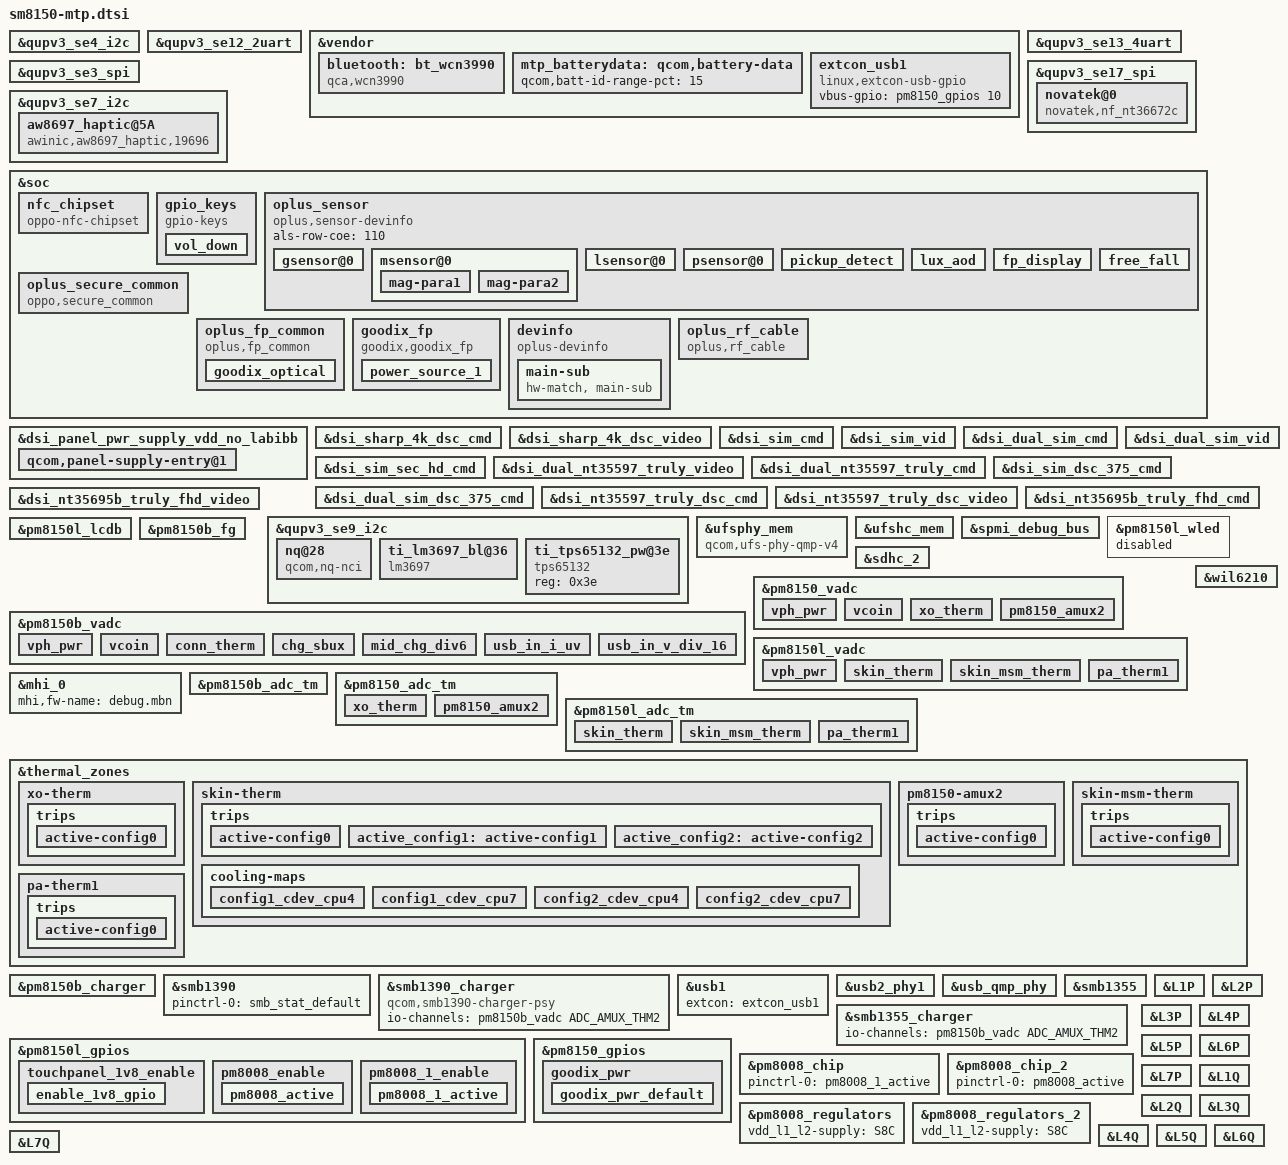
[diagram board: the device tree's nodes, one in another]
/* Copyright (c) 2017-2020, The Linux Foundation. All rights reserved.
 *
 * This program is free software; you can redistribute it and/or modify
 * it under the terms of the GNU General Public License version 2 and
 * only version 2 as published by the Free Software Foundation.
 *
 * This program is distributed in the hope that it will be useful,
 * but WITHOUT ANY WARRANTY; without even the implied warranty of
 * MERCHANTABILITY or FITNESS FOR A PARTICULAR PURPOSE.  See the
 * GNU General Public License for more details.
 */

#include <dt-bindings/gpio/gpio.h>
#include <dt-bindings/input/input.h>

#include "sm8150-pmic-overlay.dtsi"
#include "sm8150-sde-display.dtsi"
#include "sm8150-camera-sensor-mtp.dtsi"
#include "sm8150-thermal-overlay.dtsi"

&qupv3_se4_i2c {
#address-cells = <1>;
#size-cells = <0>;

#include "smb1390.dtsi"
#include "smb1355.dtsi"
/*#ifdef VENDOR_EDIT*/
/*zhixian.Mai@camera, 2019/06/21, Add for pm8008 driver*/
#include "pm8008.dtsi"
/*#endif*/
};

&qupv3_se12_2uart {
	status = "ok";
};

&vendor {
	bluetooth: bt_wcn3990 {
		compatible = "qca,wcn3990";
		qca,bt-vdd-core-supply = <&pm8150_l7>;
		qca,bt-vdd-pa-supply = <&pm8150l_l2>;
		qca,bt-vdd-ldo-supply = <&pm8150l_l11>;

		qca,bt-vdd-core-voltage-level = <1800000 1800000>;
		qca,bt-vdd-pa-voltage-level = <1304000 1304000>;
		qca,bt-vdd-ldo-voltage-level = <3312000 3312000>;

		qca,bt-vdd-core-current-level = <0>; /* LPM/PFM */
		qca,bt-vdd-pa-current-level = <0>; /* LPM/PFM */
		qca,bt-vdd-ldo-current-level = <0>; /* LPM/PFM */
	};

	mtp_batterydata: qcom,battery-data {
		qcom,batt-id-range-pct = <15>;
		#include "fg-gen4-batterydata-alium-3600mah.dtsi"
	};

	extcon_usb1: extcon_usb1 {
		compatible = "linux,extcon-usb-gpio";
		vbus-gpio = <&pm8150_gpios 10 GPIO_ACTIVE_HIGH>;
		//id-gpio = <&tlmm 101 GPIO_ACTIVE_HIGH>;
		//#ifdef VENDOR_EDIT /* tongfeng.Huang@BSP.CHG.Basic, 2018/01/08,  Add for charging chgID */
		//vbus-out-gpio = <&pm8150_gpios 9 GPIO_ACTIVE_HIGH>;
		//#endif

		pinctrl-names = "default";
		/*#ifdef VENDOR_EDIT*/
		//modify by Long.Liu 20190101, for fingerprint power gpio
		//pinctrl-0 = <&usb2_vbus_det_default
		//	     &usb2_id_det_default
		//	     &usb2_vbus_boost_default>;
		/*#endif*/
	};
};

&qupv3_se13_4uart {
	status = "ok";
};

&qupv3_se3_spi {
	status = "ok";
};

&qupv3_se4_i2c {
	status = "ok";
};
/*liuchao@BSP.TP.Function, 2019/11/27, add for novatek noflash TP*/
&qupv3_se17_spi {
	/* Himax device tree node */
	status = "ok";
	#address-cells = <1>;
	#size-cells = <0>;
	
	novatek@0 {
		compatible = "novatek,nf_nt36672c";
		reg = <0>;
		chip-name = "NT36672C_NF";
		status = "ok";

		spi-max-frequency = <15000000>; //4800000,9600000,15000000,19200000
		reset-gpio = <&tlmm 54 0x00>;
		interrupt-parent = <&tlmm>;
		interrupts = <122 0x0>;
		irq-gpio = <&tlmm 122 0x2002>;
		/*lcd-reset-gpio = <&tlmm 56 0x00>;*/
		cs-gpio = <&tlmm 58 0x01>;
		touchpanel,tx-rx-num = <18 36>;
		touchpanel,max-num-support = <10>;
		touchpanel,panel-coords = <1080 2400>;
		touchpanel,display-coords = <1080 2400>;
		touchpanel,touchmajor-limit = <0 54>;

		pinctrl-names = "default", "suspend";
		pinctrl-0 = <&ts_int_active &ts_reset_active>;
		pinctrl-1 = <&ts_int_suspend &ts_reset_suspend>;
                vid_len = <7>;
                tp_type = <6>;// type of tp_dev ,TP_JDI = 6;
                platform_support_project = <19696 19751 19752 19753 19700>;
                platform_support_project_dir = <19696 20682 20682 20682 20682>;
                platform_support_project_commandline = "nt36672c", "nt36672c", "nt36672c", "nt36672c", "nt36672c";

		incell_screen;
		fw_edge_limit_support;
		black_gesture_support;
		charger_pump_support;
		headset_pump_support;
		esd_handle_support;
		//spurious_fingerprint_support;
		//lcd_trigger_fp_check;
		black_gesture_test_support;
		noflash_support;
		smart_gesture_support;
		new_set_irq_wake_support;
		pressure_report_support;
		fw_update_app_support;
		game_switch_support;
		drlimit_remove_support;
		lcd_trigger_load_tp_fw_support;
		fw_update_in_probe_with_headfile;
		touchpanel,button-type = <4>;
		cs_gpio_need_pull;
	};
};
//#ifdef OPLUS_FEATURE_TP_BASIC
//#Chen.Pan@BSP.CHG.Misc, 2020/09/29, modify for aw8697
&qupv3_se7_i2c  {
    status = "okay";
	/* AWINIC AW8697 Haptic */
	aw8697_haptic@5A {
		compatible = "awinic,aw8697_haptic,19696";
		reg = <0x5A>;
		reset-gpio = <&tlmm 116 0>;
		irq-gpio = <&tlmm 24 0>;
		status = "okay";
        qcom,device_id = <832>;//19065

		pinctrl-names = "default";
		pinctrl-0 = <&aw_irq_gpio_default>;
	};
	/* AWINIC AW8697 Haptic End */
};
//#endif
&soc {
	//#ifdef OPLUS_FEATURE_CONNFCSOFT
	//#Zhangnan@Connectivity.NFC.BASIC.8126, 2019/09/09, Modify for : RTCID:2896930 CON_NFC_SOFT
	nfc_chipset {
		compatible = "oppo-nfc-chipset";
		chipset-19696-32 = "SN100T";
		chipset-19696-33 = "SN100T";
		chipset-19696-34 = "SN100T";
	};
	//#endif /* OPLUS_FEATURE_CONNFCSOFT */
	gpio_keys {
		compatible = "gpio-keys";
		label = "gpio-keys";

		pinctrl-names = "default";
		pinctrl-0 = <&key_vol_down_default>;

		vol_down {
			label = "volume_down";
			gpios = <&pm8150_gpios 7 GPIO_ACTIVE_LOW>;
			linux,input-type = <1>;
			linux,code = <KEY_VOLUMEDOWN>;
			gpio-key,wakeup;
			debounce-interval = <15>;
			linux,can-disable;
		};
	};

	//#ifdef OPLUS_FEATURE_SENSOR_SMEM
	/*yajie.chen @BSP.sensor, 2020/04/03, Add for sensor dts*/
	/*enum sensor_id { OPPO_ACCEL,OPPO_GYRO,OPPO_MAG,OPPO_LIGHT,OPPO_PROXIMITY,OPPO_SAR,OPPO_CT,OPPO_BAROMETER,SENSORS_NUM};*/
	oplus_sensor {
		compatible = "oplus,sensor-devinfo";
		als-row-coe = <110>;
		/*enum {LSM6DSM = 0x01, BMI160 = 0x02, LSM6DS3 = 0x04};*/
		gsensor@0 {
			sensor-name = <0x01>;//LSM6DSM
			sensor-direction = <6>;
			sensor-index = <0>;//source num
			sensor-type = <0>;//OPPO_ACCEL
		};
		/* enum {AKM0991X = 0x01, MMC5603 = 0x02};*/
		msensor@0 {
			sensor-name = <0x2>;//MMC5603
			sensor-direction = <0>;
			sensor-index = <1>;
			sensor-type = <2>;//OPPO_MAG
			mag-para1 {
				parameter-number= <18>;
				modem-type-num = <2>;
				match-modem-type = <10 11>; //modem-type  19711=10, 19698=11 those modemType use NFC
				soft-mag-parameter = <9614 0 2741 0 201 1 1436 0 12174 0 160 0 2063 0 1756 1 11951 0>;//e00 sign e01 sign ...
			};
			mag-para2 {
				parameter-number= <18>;
				modem-type-num = <2>;
				match-modem-type = <14 15>; //modem-type  19710=14, 19696=15 those modemType not use NFC
				soft-mag-parameter = <9995 0 64 0 256 1 14 1 10395 0 26 0 232 0 346 1 10810 0>;//e00 sign e01 sign...
			};
		};
		/*enum {STK3A5X=0x01,TCS3701=0x02,TCS3408=0x04};*/
		lsensor@0 {
			sensor-name = <0x01>;
			sensor-index = <0>;
			sensor-type = <3>;//OPPO_LIGHT
			bus-number = <3>;
			irq-number = <120>;
			als-type = <1>;//<1-normal;2-under screen;3-normal needed compensation>
			is-unit-device = <1>;//<1-alsps unit device;0-separate device>
			is-als-dri = <0>;//<0-polling 1-irq>
			als-factor = <1000>;
			is_als_initialed = <0>;
			als_buffer_length = <10>;
		};
		psensor@0 {
			sensor-name = <0x1>;//STK33502
			sensor-index = <0>;
			sensor-type = <4>;//OPPO_PROXIMITY
			bus-number = <3>;
			irq-number = <120>;
			ps-type = <1>;
			ps_saturation = <2600>;
			is_need_close_pd = <1>;
			//parameter start
			//dt
			low_step = <300>;
			high_step = <400>;
			low_limit = <650>;
			high_limit = <1050>;
			dirty_low_step = <300>;
			dirty_high_step = <400>;
			ps_dirty_limit = <1800>;
			ps_ir_limit = <2000>;
			ps_adjust_min = <0>;
			ps_adjust_max = <1850>;
			sampling_count = <5>;
			step_max = <400>;
			step_min = <20>;
			step_div = <2000>;
			anti_shake_delta = <70>;
			//dc
			dynamic_cali_max = <2000>;
			raw2offset_radio = <1000>;
			offset_max = <60000>;
			offset_range_min = <0>;
			offset_range_max = <65535>;
			force_cali_limit = <2000>;
			cali_jitter_limit = <20>;
			cal_offset_margin = <3000>;
			//parameter end
			//sensor-reg start
			parameter-number = <4>;
			sensor-reg = <0x01 0x32
						  0x05 0x20>; //override special reg
		};
		/*virtual sensor
		enum sensor_algo_id {
			OPPO_PICKUP_DETECT,
			OPPO_LUX_AOD,
			OPPO_TP_GESTURE,
			OPPO_FP_DISPLAY,
			OPPO_FREE_FALL,
			OPPO_CAMERA_PROTECT,
			SENSOR_ALGO_NUM
		}*/
		pickup_detect {
			sensor-type = <0>;//OPPO_PICKUP_DETECT
			is-virtual-sensor;
			is-need-prox = <1>;//0 - disable; 1 - enable
			prox-type = <0>;//prox_type: 0 - proximity; 1 - proximity_fake
		};
		lux_aod {
			sensor-type = <1>; //OPPO_LUX_AOD
			is-virtual-sensor;
			thrd-low = <12>;
			thrd-high = <50>;
			als-type = <1>; // 0 - wise_light; 1 - ambient_light
		};
		fp_display {
			sensor-type = <3>; //OPPO_FP_DISPLAY
			is-virtual-sensor;
			prox-type = <0>; // 0 - proximity; 1 - proximity_fake
		};
		free_fall {
			sensor-type = <4>; //OPPO_FREE_FALL
			is-virtual-sensor;
		};
	};
	//#endif /*OPLUS_FEATURE_SENSOR_SMEM*/

//	qcom,qbt1000 {
//		compatible = "qcom,qbt1000";
//		clock-names = "core", "iface";
//		clock-frequency = <25000000>;
//		qcom,ipc-gpio = <&tlmm 118 0>;
//		pinctrl-names = "default";
//		pinctrl-0 = <&key_home_default>;
//		qcom,finger-detect-gpio = <&pm8150_gpios 1 0>;
//	};

	/* #ifdef OPLUS_FEATURE_SECURITY_COMMON */
	/* zhangjian@BSP.Fingerprint.Secure 2020/10/12, add for secure proc */
	oplus_secure_common {
		compatible = "oppo,secure_common";
	};
	/* #endif OPLUS_FEATURE_SECURITY_COMMON */

        oplus_fp_common {
                compatible = "oplus,fp_common";
		oplus,fp_gpio_num = <1>; /* the gpio number of fingerprint id used */
                oplus,fp_gpio_0 = <&tlmm 130 0x0>;
                pinctrl-names = "default";
                pinctrl-0 = <&gpio_id2_default>;
                goodix_optical {
                        oplus,fp-id = <0>; /* fp id mapping table */
                        vendor-chip = <16>; /* please refer to the struct fp_vendor_t in oppo_fp_commmon.n */
                        eng-menu = "-1,-1"; /* represents SNR, inclination test item in engineer menu, and 0/1 means off/on */
                        chip-name = "G_3626";  /* /proc/fp_id, will be displayed in engineer menu  */
                };
        };

	/*#ifdef VENDOR_EDIT duchong@Bsp.Fingerprint.Basic 2020-8-12 add for goodix TEE */
        goodix_fp {
                status = "ok";
                compatible = "goodix,goodix_fp";
                interrupt-parent = <&tlmm>;
                interrupts = <118 0>;

                ldo-supply = <&pm8150l_l9>; // pm660l_l5 for goodix_fp 
                ldo-config = <2960000 2960000 50000>;

                //gpio-power = <&pm8150_gpios 9 GPIO_ACTIVE_LOW>;
                goodix,gpio_irq = <&tlmm 118 0x1>;
                goodix,gpio_reset = <&tlmm 121 0x0>;
                pinctrl-names = "default";
                pinctrl-0 = <&gpio_goodix_irq_default>;
                pinctrl-1 = <&goodix_pwr_default>;

                power-num = <2> ;
                power_source_1 {
                        power-mode = <1>;   /* 1 = ldo power, refer to oplus_fp_common.h*/
                        power-name = "ldo";
                        power-config = "ldo-config";
                        delay-time = <0>;
                };
        };
        //#endif /*VENDOR_EDIT*/

/*ifdef VENDOR_EDIT*/
//Added by Tong.han@Bsp.Group.Tp for device-info,2015-4-13
	devinfo {
		compatible = "oplus-devinfo";
		pinctrl-names = "active","sleep";
		pinctrl-0 = <&hw_sub1_pullup>;
		pinctrl-1 = <&hw_sub1_pulldown>;

		main-sub {
			compatible = "hw-match, main-sub";
			aboard-gpio0 = <&pm8150b_gpios 8 0x00>;
			aboard-patterns = <0 1>;
			match-projects = <19781 19696>;
		};
	};
/*endif*/

	/* #ifdef OPLUS_FEATURE_TP_BASIC */
	/* Qingwen.Liu@RM.BSP.Basic 2020/10/27 modify for oppo rf cable monitor */
	oplus_rf_cable {
		compatible = "oplus,rf_cable";
		interrupt-parent = <&tlmm>;
		rf_cable_support_num = <1>;
		rf,cable0-gpio = <&tlmm 26 0>;
		rf,cable-support-timer = <0>;
		pinctrl-names = "rf_cable_active";
		pinctrl-0 = <&rf_cable0_active>;
	};
	/* #endif OPLUS_FEATURE_TP_BASIC */
};

&dsi_panel_pwr_supply_vdd_no_labibb {
	qcom,panel-supply-entry@1 {
		qcom,supply-min-voltage = <1800000>;
		qcom,supply-max-voltage = <1800000>;
	};
};

&dsi_sharp_4k_dsc_cmd {
	qcom,panel-supply-entries = <&dsi_panel_pwr_supply>;
	qcom,mdss-dsi-bl-pmic-control-type = "bl_ctrl_wled";
	qcom,mdss-dsi-bl-min-level = <1>;
	qcom,mdss-dsi-bl-max-level = <4095>;
	qcom,mdss-dsi-mode-sel-gpio-state = "dual_port";
	qcom,panel-mode-gpio = <&tlmm 7 0>;
	qcom,platform-te-gpio = <&tlmm 8 0>;
	qcom,platform-reset-gpio = <&tlmm 6 0>;
};

&dsi_sharp_4k_dsc_video {
	qcom,panel-supply-entries = <&dsi_panel_pwr_supply>;
	qcom,mdss-dsi-bl-pmic-control-type = "bl_ctrl_wled";
	qcom,mdss-dsi-bl-min-level = <1>;
	qcom,mdss-dsi-bl-max-level = <4095>;
	qcom,mdss-dsi-mode-sel-gpio-state = "dual_port";
	qcom,panel-mode-gpio = <&tlmm 7 0>;
	qcom,platform-te-gpio = <&tlmm 8 0>;
	qcom,platform-reset-gpio = <&tlmm 6 0>;
};

&dsi_sim_cmd {
	qcom,panel-supply-entries = <&dsi_panel_pwr_supply>;
	qcom,mdss-dsi-bl-pmic-control-type = "bl_ctrl_dcs";
	qcom,platform-reset-gpio = <&tlmm 6 0>;
};

&dsi_sim_vid {
	qcom,panel-supply-entries = <&dsi_panel_pwr_supply>;
	qcom,mdss-dsi-bl-pmic-control-type = "bl_ctrl_dcs";
	qcom,platform-reset-gpio = <&tlmm 6 0>;
};

&dsi_dual_sim_cmd {
	qcom,panel-supply-entries = <&dsi_panel_pwr_supply>;
	qcom,mdss-dsi-bl-pmic-control-type = "bl_ctrl_dcs";
	qcom,platform-reset-gpio = <&tlmm 6 0>;
};

&dsi_dual_sim_vid {
	qcom,panel-supply-entries = <&dsi_panel_pwr_supply>;
	qcom,mdss-dsi-bl-pmic-control-type = "bl_ctrl_dcs";
	qcom,platform-reset-gpio = <&tlmm 6 0>;
};

&dsi_sim_sec_hd_cmd {
	qcom,panel-supply-entries = <&dsi_panel_pwr_supply>;
	qcom,panel-sec-supply-entries = <&dsi_panel_pwr_supply_vdd_no_labibb>;
	qcom,mdss-dsi-bl-pmic-control-type = "bl_ctrl_wled";
	qcom,mdss-dsi-bl-min-level = <1>;
	qcom,mdss-dsi-bl-max-level = <4095>;
	qcom,mdss-dsi-mode-sel-gpio-state = "single_port";
	qcom,panel-mode-gpio = <&tlmm 7 0>;
	qcom,platform-reset-gpio = <&tlmm 6 0>;
	qcom,panel-sec-mode-gpio = <&tlmm 77 0>;
	qcom,platform-sec-reset-gpio = <&tlmm 66 0>;
};

&dsi_dual_nt35597_truly_video {
	qcom,panel-supply-entries = <&dsi_panel_pwr_supply>;
	qcom,mdss-dsi-bl-pmic-control-type = "bl_ctrl_wled";
	qcom,mdss-dsi-bl-min-level = <1>;
	qcom,mdss-dsi-bl-max-level = <4095>;
	qcom,mdss-dsi-mode-sel-gpio-state = "dual_port";
	qcom,panel-mode-gpio = <&tlmm 7 0>;
	qcom,platform-te-gpio = <&tlmm 8 0>;
	qcom,platform-reset-gpio = <&tlmm 6 0>;
};

&dsi_dual_nt35597_truly_cmd {
	qcom,panel-supply-entries = <&dsi_panel_pwr_supply>;
	qcom,mdss-dsi-bl-pmic-control-type = "bl_ctrl_wled";
	qcom,mdss-dsi-bl-min-level = <1>;
	qcom,mdss-dsi-bl-max-level = <4095>;
	qcom,mdss-dsi-mode-sel-gpio-state = "dual_port";
	qcom,panel-mode-gpio = <&tlmm 7 0>;
	qcom,platform-te-gpio = <&tlmm 8 0>;
	qcom,platform-reset-gpio = <&tlmm 6 0>;
};

&dsi_sim_dsc_375_cmd {
	qcom,panel-supply-entries = <&dsi_panel_pwr_supply>;
	qcom,mdss-dsi-bl-pmic-control-type = "bl_ctrl_dcs";
	qcom,platform-reset-gpio = <&tlmm 6 0>;
};

&dsi_dual_sim_dsc_375_cmd {
	qcom,panel-supply-entries = <&dsi_panel_pwr_supply>;
	qcom,mdss-dsi-bl-pmic-control-type = "bl_ctrl_dcs";
	qcom,platform-reset-gpio = <&tlmm 6 0>;
};

&dsi_nt35597_truly_dsc_cmd {
	qcom,panel-supply-entries = <&dsi_panel_pwr_supply>;
	qcom,mdss-dsi-bl-pmic-control-type = "bl_ctrl_wled";
	qcom,mdss-dsi-bl-min-level = <1>;
	qcom,mdss-dsi-bl-max-level = <4095>;
	qcom,mdss-dsi-mode-sel-gpio-state = "single_port";
	qcom,panel-mode-gpio = <&tlmm 7 0>;
	qcom,platform-te-gpio = <&tlmm 8 0>;
	qcom,platform-reset-gpio = <&tlmm 6 0>;
};

&dsi_nt35597_truly_dsc_video {
	qcom,panel-supply-entries = <&dsi_panel_pwr_supply>;
	qcom,mdss-dsi-bl-pmic-control-type = "bl_ctrl_wled";
	qcom,mdss-dsi-bl-min-level = <1>;
	qcom,mdss-dsi-bl-max-level = <4095>;
	qcom,mdss-dsi-mode-sel-gpio-state = "single_port";
	qcom,panel-mode-gpio = <&tlmm 7 0>;
	qcom,platform-te-gpio = <&tlmm 8 0>;
	qcom,platform-reset-gpio = <&tlmm 6 0>;
};

&dsi_nt35695b_truly_fhd_cmd {
	qcom,panel-supply-entries = <&dsi_panel_pwr_supply>;
	qcom,mdss-dsi-bl-pmic-control-type = "bl_ctrl_wled";
	qcom,mdss-dsi-bl-min-level = <1>;
	qcom,mdss-dsi-bl-max-level = <4095>;
	qcom,mdss-dsi-mode-sel-gpio-state = "single_port";
	qcom,panel-mode-gpio = <&tlmm 7 0>;
	qcom,platform-te-gpio = <&tlmm 8 0>;
	qcom,platform-reset-gpio = <&tlmm 6 0>;
};

&dsi_nt35695b_truly_fhd_video {
	qcom,panel-supply-entries = <&dsi_panel_pwr_supply>;
	qcom,mdss-dsi-bl-pmic-control-type = "bl_ctrl_wled";
	qcom,mdss-dsi-bl-min-level = <1>;
	qcom,mdss-dsi-bl-max-level = <4095>;
	qcom,mdss-dsi-mode-sel-gpio-state = "single_port";
	qcom,panel-mode-gpio = <&tlmm 7 0>;
	qcom,platform-te-gpio = <&tlmm 8 0>;
	qcom,platform-reset-gpio = <&tlmm 6 0>;
};

//#ifdef OPLUS_NFC_BRINGUP
//ruhong.huang@CN.NFC.Basic.Hardware.2046983, 2019/06/18,
//Modify for dtsi for NXP NFC set VEN pin to gpio36 and remove esepwr
&qupv3_se9_i2c {
	status = "ok";

	#address-cells = <1>;
	#size-cells = <0>;
	nq@28 {
		compatible = "qcom,nq-nci";
		reg = <0x28>;
		qcom,nq-irq = <&tlmm 47 0x00>;
		qcom,nq-ven = <&tlmm 36 0x00>;
		qcom,nq-firm = <&tlmm 48 0x00>;
		qcom,nq-clkreq = <&tlmm 113 0x00>;
		//qcom,nq-esepwr = <&tlmm 42 0x00>;
		interrupt-parent = <&tlmm>;
		interrupts = <47 0>;
		interrupt-names = "nfc_irq";
		pinctrl-names = "nfc_active", "nfc_suspend";
		pinctrl-0 = <&nfc_int_active &nfc_enable_active
					&nfc_clk_req_active>;
		pinctrl-1 = <&nfc_int_suspend &nfc_enable_suspend
					&nfc_clk_req_suspend>;
	};
//#endif /* OPLUS_NFC_BRINGUP */
//#ifdef VENDOR_EDIT
// Jinzhu.Han@MM.Display.LCD.Machine 2019-10-14 add nodes for backlight and lcd power
	ti_lm3697_bl@36 {
		compatible = "lm3697";
		reg = <0x36>;
		ti,bl-enable-gpio = <&pm8150l_gpios 11 0>;
	};

	ti_tps65132_pw@3e {
		compatible = "tps65132";
		reg = <0x3e>;
		status = "okay";
		//enp-gpio = <&pm8150l_gpios 2 0>;
		//enn-gpio = <&pm8150l_gpios 1 0>;
	};
//#endif
};

&ufsphy_mem {
	compatible = "qcom,ufs-phy-qmp-v4";

	vdda-phy-supply = <&pm8150_l5>;
	vdda-phy-always-on;
	vdda-pll-supply = <&pm8150l_l3>;
	vdda-phy-max-microamp = <90200>;
	vdda-pll-max-microamp = <19000>;

	status = "ok";
};

&ufshc_mem {
	vdd-hba-supply = <&ufs_phy_gdsc>;
	vdd-hba-fixed-regulator;
	vcc-supply = <&pm8150_l10>;
	vcc-voltage-level = <2504000 2950000>;
	vcc-low-voltage-sup;
	vccq-supply = <&pm8150_l9>;
	vccq2-supply = <&pm8150_s4>;
	vcc-max-microamp = <750000>;
	vccq-max-microamp = <700000>;
	vccq2-max-microamp = <750000>;

	qcom,vddp-ref-clk-supply = <&pm8150_l9>;
	qcom,vddp-ref-clk-max-microamp = <100>;
	qcom,vccq-parent-supply = <&pm8150l_s8>;
	qcom,vccq-parent-max-microamp = <210000>;

	status = "ok";
};

&spmi_debug_bus {
	status = "ok";
};

&pm8150l_wled {
	qcom,string-cfg= <7>;
	qcom,leds-per-string = <6>;
//#ifdef OPLUS_BUG_DEBUG
/* xupengcheng@MULTIMEDIA.DISPLAY.LCD, 2020/09/23, add for 19696 backlight IC lm3697*/
	status = "disabled";
//#endif /*OPLUS_BUG_DEBUG*/
};

&pm8150l_lcdb {
	status = "ok";
};

&pm8150b_fg {
	qcom,battery-data = <&mtp_batterydata>;
	qcom,hold-soc-while-full;
	qcom,linearize-soc;
	qcom,five-pin-battery;
	qcom,cl-wt-enable;
	/* ESR fast calibration */
	qcom,fg-esr-timer-chg-fast = <0 7>;
	qcom,fg-esr-timer-dischg-fast = <0 7>;
	qcom,fg-esr-timer-chg-slow = <0 96>;
	qcom,fg-esr-timer-dischg-slow = <0 96>;
	qcom,fg-esr-cal-soc-thresh = <26 230>;
	qcom,fg-esr-cal-temp-thresh = <10 40>;
};

&sdhc_2 {
	vdd-supply = <&pm8150l_l9>;
	qcom,vdd-voltage-level = <2950000 2960000>;
	qcom,vdd-current-level = <200 800000>;

	vdd-io-supply = <&pm8150l_l6>;
	qcom,vdd-io-voltage-level = <1808000 2960000>;
	qcom,vdd-io-current-level = <200 22000>;

	pinctrl-names = "active", "sleep";
	pinctrl-0 = <&sdc2_clk_on  &sdc2_cmd_on &sdc2_data_on &storage_cd>;
	pinctrl-1 = <&sdc2_clk_off &sdc2_cmd_off &sdc2_data_off &storage_cd>;

	cd-gpios = <&tlmm 96 GPIO_ACTIVE_LOW>;

	status = "ok";
};

&pm8150b_vadc {
	vph_pwr {
		reg = <ADC_VPH_PWR>;
		label = "vph_pwr";
		qcom,pre-scaling = <1 3>;
	};

//	wp_therm {
//		reg = <ADC_AMUX_THM1_PU2>;
//		label = "wp_therm";
//		qcom,ratiometric;
//		qcom,hw-settle-time = <200>;
//		qcom,pre-scaling = <1 1>;
//	};

	vcoin {
		reg = <ADC_VCOIN>;
		label = "vcoin";
		qcom,pre-scaling = <1 3>;
	};

	conn_therm {
		reg = <ADC_AMUX_THM3_PU2>;
		label = "conn_therm";
		qcom,ratiometric;
		qcom,hw-settle-time = <200>;
		qcom,pre-scaling = <1 1>;
	};

	chg_sbux {
		reg = <ADC_SBUx>;
		label = "chg_sbux";
		qcom,pre-scaling = <1 3>;
	};

	mid_chg_div6 {
		reg = <ADC_MID_CHG_DIV6>;
		label = "chg_mid";
		qcom,pre-scaling = <1 6>;
	};

	usb_in_i_uv {
		reg = <ADC_USB_IN_I>;
		label = "usb_in_i_uv";
		qcom,pre-scaling = <1 1>;
	};

	usb_in_v_div_16 {
		reg = <ADC_USB_IN_V_16>;
		label = "usb_in_v_div_16";
		qcom,pre-scaling = <1 16>;
	};
};

&pm8150_vadc {
	vph_pwr {
		reg = <ADC_VPH_PWR>;
		label = "vph_pwr";
		qcom,pre-scaling = <1 3>;
	};

	vcoin {
		reg = <ADC_VCOIN>;
		label = "vcoin";
		qcom,pre-scaling = <1 3>;
	};

	xo_therm {
		reg = <ADC_XO_THERM_PU2>;
		label = "xo_therm";
		qcom,ratiometric;
		qcom,hw-settle-time = <200>;
		qcom,pre-scaling = <1 1>;
	};

//	skin_therm {
//		reg = <ADC_AMUX_THM1_PU2>;
//		label = "skin_therm";
//		qcom,ratiometric;
//		qcom,hw-settle-time = <200>;
//		qcom,pre-scaling = <1 1>;
//	};

	pm8150_amux2 {
		reg = <ADC_AMUX_THM2_PU2>;
		label = "pm8150_amux2";
		qcom,ratiometric;
		qcom,hw-settle-time = <200>;
		qcom,pre-scaling = <1 1>;
	};
};

&pm8150l_vadc {
	vph_pwr {
		reg = <ADC_VPH_PWR>;
		label = "vph_pwr";
		qcom,pre-scaling = <1 3>;
	};

	skin_therm {
		reg = <ADC_AMUX_THM1_PU2>;
		label = "skin_therm";
		qcom,ratiometric;
		qcom,hw-settle-time = <200>;
		qcom,pre-scaling = <1 1>;
	};

	skin_msm_therm {
		reg = <ADC_AMUX_THM2_PU2>;
		label = "skin_msm_therm";
		qcom,ratiometric;
		qcom,hw-settle-time = <200>;
		qcom,pre-scaling = <1 1>;
	};

	pa_therm1 {
		reg = <ADC_AMUX_THM3_PU2>;
		label = "pa_therm1";
		qcom,ratiometric;
		qcom,hw-settle-time = <200>;
		qcom,pre-scaling = <1 1>;
	};
};

&wil6210 {
	status = "ok";
};

&mhi_0 {
	mhi,fw-name = "debug.mbn";
};

&pm8150b_adc_tm {
//	wp_therm {
//		reg = <ADC_AMUX_THM1_PU2>;
//		qcom,ratiometric;
//		qcom,hw-settle-time = <200>;
//	};
};

&pm8150_adc_tm {
	xo_therm {
		reg = <ADC_XO_THERM_PU2>;
		qcom,ratiometric;
		qcom,hw-settle-time = <200>;
	};

//	skin_therm {
//		reg = <ADC_AMUX_THM1_PU2>;
//		qcom,ratiometric;
//		qcom,hw-settle-time = <200>;
//	};

	pm8150_amux2 {
		reg = <ADC_AMUX_THM2_PU2>;
		qcom,ratiometric;
		qcom,hw-settle-time = <200>;
	};
};

&pm8150l_adc_tm {
	skin_therm {
		reg = <ADC_AMUX_THM1_PU2>;
		qcom,ratiometric;
		qcom,hw-settle-time = <200>;
	};

	skin_msm_therm {
		reg = <ADC_AMUX_THM2_PU2>;
		qcom,ratiometric;
		qcom,hw-settle-time = <200>;
	};

	pa_therm1 {
		reg = <ADC_AMUX_THM3_PU2>;
		qcom,ratiometric;
		qcom,hw-settle-time = <200>;
	};
};

&thermal_zones {
//	wp-therm {
//		polling-delay-passive = <0>;
//		polling-delay = <0>;
//		thermal-governor = "user_space";
//		thermal-sensors = <&pm8150b_adc_tm ADC_AMUX_THM1_PU2>;
//		wake-capable-sensor;
//		trips {
//			active-config0 {
//				temperature = <125000>;
//				hysteresis = <1000>;
//				type = "passive";
//			};
//		};
//	};

	xo-therm {
		polling-delay-passive = <0>;
		polling-delay = <0>;
		thermal-governor = "user_space";
		thermal-sensors = <&pm8150_adc_tm ADC_XO_THERM_PU2>;
		wake-capable-sensor;
		trips {
			active-config0 {
				temperature = <125000>;
				hysteresis = <1000>;
				type = "passive";
			};
		};
	};

	skin-therm {
		polling-delay-passive = <50>;
		polling-delay = <200>;
		thermal-governor = "step_wise";
		thermal-sensors = <&pm8150l_adc_tm ADC_AMUX_THM1_PU2>;
		/* #ifdef VENDOR_EDIT */
		temp-track;
		/* #endif */
		wake-capable-sensor;
		trips {
			active-config0 {
				temperature = <125000>;
				hysteresis = <1000>;
				type = "passive";
			};
			active_config1: active-config1 {
				temperature = <44000>;
				hysteresis = <1000>;
				type = "passive";
			};
			active_config2: active-config2 {
				temperature = <46000>;
				hysteresis = <1000>;
				type = "passive";
			};
		};
		cooling-maps {
			config1_cdev_cpu4 {
				trip = <&active_config1>;
				cooling-device = <&CPU4 THERMAL_NO_LIMIT 7>;
			};
			config1_cdev_cpu7 {
				trip = <&active_config1>;
				cooling-device = <&CPU7 THERMAL_NO_LIMIT 10>;
			};
			config2_cdev_cpu4 {
				trip = <&active_config2>;
				cooling-device = <&CPU4 THERMAL_NO_LIMIT 12>;
			};
			config2_cdev_cpu7 {
				trip = <&active_config2>;
				cooling-device = <&CPU7 THERMAL_NO_LIMIT 15>;
			};
		};
	};

	pm8150-amux2 {
		polling-delay-passive = <0>;
		polling-delay = <0>;
		thermal-governor = "user_space";
		thermal-sensors = <&pm8150_adc_tm ADC_AMUX_THM2_PU2>;
		wake-capable-sensor;
		trips {
			active-config0 {
				temperature = <125000>;
				hysteresis = <1000>;
				type = "passive";
			};
		};
	};

//	camera-flash-therm {
//		polling-delay-passive = <0>;
//		polling-delay = <0>;
//		thermal-governor = "user_space";
//		thermal-sensors = <&pm8150l_adc_tm ADC_AMUX_THM1_PU2>;
//		wake-capable-sensor;
//		trips {
//			active-config0 {
//				temperature = <125000>;
//				hysteresis = <1000>;
//				type = "passive";
//			};
//		};
//	};

	skin-msm-therm {
		polling-delay-passive = <0>;
		polling-delay = <0>;
		thermal-governor = "user_space";
		thermal-sensors = <&pm8150l_adc_tm ADC_AMUX_THM2_PU2>;
		wake-capable-sensor;
		trips {
			active-config0 {
				temperature = <125000>;
				hysteresis = <1000>;
				type = "passive";
			};
		};
	};

	pa-therm1 {
		polling-delay-passive = <0>;
		polling-delay = <0>;
		thermal-governor = "user_space";
		thermal-sensors = <&pm8150l_adc_tm ADC_AMUX_THM3_PU2>;
		wake-capable-sensor;
		trips {
			active-config0 {
				temperature = <125000>;
				hysteresis = <1000>;
				type = "passive";
			};
		};
	};
};

&pm8150b_charger {
	qcom,sec-charger-config = <3>;
	qcom,auto-recharge-soc = <98>;
	io-channels = <&pm8150b_vadc ADC_MID_CHG_DIV6>,
		      <&pm8150b_vadc ADC_USB_IN_I>,
		      <&pm8150b_vadc ADC_SBUx>,
		      <&pm8150b_vadc ADC_VPH_PWR>,
//#ifdef VENDOR_EDIT /* tongfeng.Huang@BSP.CHG.Basic, 2016/12/26,  Add for charging chgID */
		      <&pm8150b_vadc ADC_CHG_TEMP>,
		      <&pm8150b_vadc ADC_USB_IN_V_16>,
			  <&pm8150b_vadc ADC_GPIO3>,
			  <&pm8150b_vadc ADC_AMUX_THM4>,
			  <&pm8150b_vadc ADC_GPIO2>;
//#else
		      //<&pm8150b_vadc ADC_CHG_TEMP>,
		      //<&pm8150b_vadc ADC_USB_IN_V_16>;
//#endif
	io-channel-names = "mid_voltage",
			   "usb_in_current",
			   "sbux_res",
			   "vph_voltage",
//#ifdef VENDOR_EDIT /* tongfeng.Huang@BSP.CHG.Basic, 2016/12/26,  Add for charging chgID */
			   "chg_temp",
			   "usb_in_voltage",
			   "chgID_voltage_adc",
			   "usb_temp_adc",
			   "usb_supplementary_temp_adc";
//#else
				///"chg_temp",
				///"usb_in_voltage";
//#endif
	qcom,battery-data = <&mtp_batterydata>;
//#ifdef VENDOR_EDIT  /* zhangkun@BSP.CHG.Basic, 2019/02/22, Add for disable water detect*/
	qcom,lpd-disable;
//#endif
	qcom,step-charging-enable;
	qcom,sw-jeita-enable;
	qcom,wd-bark-time-secs = <16>;
	qcom,suspend-input-on-debug-batt;
};

&smb1390 {
	pinctrl-names = "default";
	pinctrl-0 = <&smb_stat_default>;
	status = "ok";
};

&smb1390_charger {
	/delete-property/ compatible;
	compatible = "qcom,smb1390-charger-psy";
	io-channels = <&pm8150b_vadc ADC_AMUX_THM2>;
	io-channel-names = "cp_die_temp";
	status = "ok";
};

&usb1 {
	extcon = <&extcon_usb1>;
	status = "ok";
};

&usb2_phy1 {
	status = "ok";
};

&usb_qmp_phy {
	status = "ok";
};

&smb1355 {
	status = "ok";
};

&smb1355_charger {
	io-channels = <&pm8150b_vadc ADC_AMUX_THM2>;
	io-channel-names = "charger_temp";
	status = "ok";
};

&pm8150l_gpios {
	touchpanel_1v8_enable{
		enable_1v8_gpio: enable_1v8_gpio {
			pins = "gpio5";//GPIO 5
			function = "normal";//
			bias-disable; //No Pull
			power-source = <0>;
			output-low; //digital output, no invert
			qcom,drive-strength = <3>; //LOW strength
			drive-push-pull;//CMOS
		};
	};
};
/* duchong@BSP.Fingerprint.Basic 2020/08/12, add for gpio of fingerprint */
&pm8150_gpios {
	goodix_pwr {
		goodix_pwr_default: goodix_pwr_default {
			pins = "gpio9";
			function = "normal";
			bias-disable; /* No Pull */
			power-source = <1>; /* VIN1 */
			output-low; /* digital output, no invert */
			input-disable; /* prevent GPIO from being set to DIO */
		};
	};
};
/*zhixian.Mai@camera, 2019/06/21, Add for pm8008 driver*/
&pm8150l_gpios {
        pm8008_enable{
                pm8008_active: pm8008_active {
                        pins = "gpio4";//GPIO 4
                        function = "normal";//
                        bias-disable; //No Pull
                        power-source = <0>;
                        output-high; //digital output, no invert
                        qcom,drive-strength = <3>; //LOW strength
                        drive-push-pull;//CMOS
                };
        };
        pm8008_1_enable{
                pm8008_1_active: pm8008_1_active {
                        pins = "gpio1";//GPIO 4
                        function = "normal";//
                        bias-disable; //No Pull
                        power-source = <0>;
                        output-high; //digital output, no invert
                        qcom,drive-strength = <3>; //LOW strength
                        drive-push-pull;//CMOS
                };
        };
};

&pm8008_chip {
	pinctrl-names = "default";
        pinctrl-0 = <&pm8008_1_active>;
};

&pm8008_chip_2 {
        pinctrl-names = "default";
	pinctrl-0 = <&pm8008_active>;
};


&pm8008_regulators {
	vdd_l1_l2-supply = <&S8C>;
};

&pm8008_regulators_2 {
	vdd_l1_l2-supply = <&S8C>;
};
&L1P {
	regulator-min-microvolt = <1100000>;
	regulator-max-microvolt = <1200000>;
	qcom,min-dropout-voltage = <100000>;
};

&L2P {
	regulator-min-microvolt = <1050000>;
	regulator-max-microvolt = <1050000>;
	qcom,min-dropout-voltage = <100000>;
};

&L3P {
	regulator-min-microvolt = <2800000>;
	regulator-max-microvolt = <2800000>;
};

&L4P {
	regulator-min-microvolt = <2800000>;
	regulator-max-microvolt = <2800000>;
};

&L5P {
	regulator-min-microvolt = <2800000>;
	regulator-max-microvolt = <2800000>;
};

&L6P {
	regulator-min-microvolt = <2800000>;
	regulator-max-microvolt = <2800000>;
};

&L7P {
	/* #ifdef VENDOR_EDIT */
	/* Long.Liu@BSP.Fingerprint.Secure 2019/09/11, add for oppo fingerprint avdd */
	regulator-min-microvolt = <3300000>;
	regulator-max-microvolt = <3300000>;
	/* #ifdef else */
	/* regulator-min-microvolt = <2800000>;  */
	/* regulator-max-microvolt = <2800000>;  */
	/* #endif VENDOR_EDIT */
};

&L1Q {
	regulator-min-microvolt = <1100000>;
	regulator-max-microvolt = <1200000>;
	qcom,min-dropout-voltage = <100000>;
};

&L2Q {
	regulator-min-microvolt = <1050000>;
	regulator-max-microvolt = <1200000>;
	qcom,min-dropout-voltage = <100000>;
};

&L3Q {
	regulator-min-microvolt = <2800000>;
	regulator-max-microvolt = <2800000>;
};

&L4Q {
	regulator-min-microvolt = <2800000>;
	regulator-max-microvolt = <2800000>;
};

&L5Q {
	regulator-min-microvolt = <2800000>;
	regulator-max-microvolt = <2800000>;
};

&L6Q {
	regulator-min-microvolt = <2800000>;
	regulator-max-microvolt = <2800000>;
};

&L7Q {
	regulator-min-microvolt = <2800000>;
	regulator-max-microvolt = <2800000>;
};

//#endif

